# M55M1 register map
File version: 1.0
Registers are 32-bit, read-write, reset 0x0 unless marked. A register's access mark holds for its fields unless they carry their own. Offsets are from the block's base; [hi:lo] are bit positions; {n}, {i} and the like mark numbered series.

## DMIC — DMIC Register Map
Base 0x40445000
0x00 DMIC_CTL reset 0xF0000000 — DMIC Control Register
0x04 DMIC_DIV reset 0x800 — DMIC Clock Divider Register
0x08 DMIC_STATUS ro reset 0x2 (reset mask 0xFFFF)
0x0C DMIC_LPPDMACTL — DMIC LPPDMA Control Register
0x10 DMIC_FIFO ro — DMIC FIFO Data Output Register
0x14 DMIC_GAINCTL0 reset 0xC000C000 — DMIC Channel 0 and 1 Volume Control Register
0x18 DMIC_GAINCTL1 reset 0xC000C000 — DMIC Channel 2 and 3 Volume Control Register

## VAD — DMIC Register Map
Base 0x40445300
0x00 VAD_SINCCTL reset 0x30000 — VAD SINC Filter Control Register
{0x4+4i} VAD_BIQCTL{i} (i=0..2) — VAD Biquad Filter Control Register {i}
0x10 VAD_CTL0 reset 0x700CC — VAD Control Register 0
0x14 VAD_CTL1 reset 0x7FFF — VAD Control Register 1
0x18 VAD_CTL2 — VAD Control Register 2
0x1C VAD_CTL3 reset 0x7FFF — VAD Control Register 3
0x20 VAD_STATUS0 ro — VAD Status Read-back Register 0
0x24 VAD_STATUS1 ro — VAD Status Read-back Register 1

## KDF — KDF Register Map
Base 0x40221000
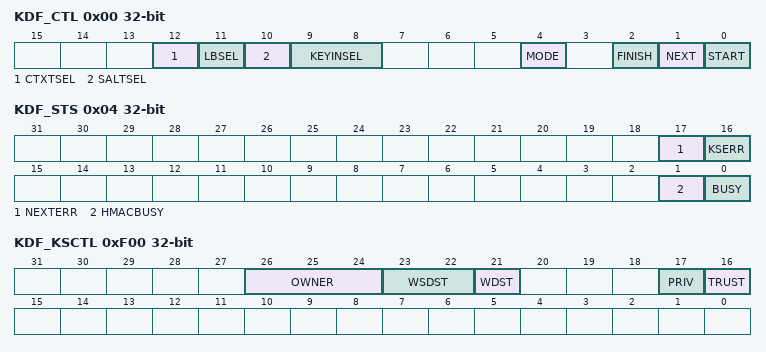
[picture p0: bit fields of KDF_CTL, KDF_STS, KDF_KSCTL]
0x00 KDF_CTL — KDF Control Register
  [12] CTXTSEL — KDF Context Selection
    0=CONTEXT from KDF_CONTEXT register; 1=CONTEXT from random value
  [11] LBSEL — KDF Label Selection
    0=LABEL from KDF_LABEL register; 1=LABEL from random value
  [10] SALTSEL — KDF Salt Selection
    0=SALT from KDF_SALT register; 1=SALT from random value
  [9:8] KEYINSEL — KDF Input Key Source Selection. Note: If KEYINSEL is 01, the NVM key is from KS OTP key 15.
    0=KEYIN from KDF_KEYIN register; 1=KEYIN from NVM (Flash)
  [4] MODE — KDF Mode Selection
    0=HKDF (RFC 5869); 1=KBKDF (NIST SP 800-108)
  [2] FINISH — KDF Next Finish
    0=No effect; 1=Finish generating the next partial key
  [1] NEXT — KDF Next Start
    0=No effect; 1=Start KDF to generate the next partial key only when BUSY is 0. BUSY flag will be set
  [0] START — KDF Start
    0=No operation; 1=Start the operation
0x04 KDF_STS ro — KDF Status Register
  [17] NEXTERR — KDF Next Generation Error Flag
    0=No error; 1=NEXT(KS_CTL[1]) times is greater than KLEN/256
  [16] KSERR — KDF Access Key Store Error Flag
    0=No error; 1=Access Key Store failed
  [1] HMACBUSY — HMAC Busy Flag
    0=HMAC engine is idle or finished; 1=HMAC engine is busy
  [0] BUSY — KDF Busy Flag
    0=KDF is idle or finished; 1=KDF is busy
0x08 KDF_KLEN — KDF Output Key Length Register
  [15:0] KLEN — Output Key Length. The maxinum is 0xFF00 (65280-bit). If KLEN is 0 or greater than the maximum, KDF will not execute.
{0x40+4i} KDF_KEYIN{i} wo (i=0..7) — KDF Input Key Word {i} Register
  [31:0] KEYIN — Input Key. For RFC 5869, input keying material is to be filled in KEYIN. For NIST SP 800-108, KI is to be filled in KEYIN.
{0x80+4i} KDF_KEYOUT{i} ro (i=0..7) — KDF Output Key Word {i} Register
  [31:0] KEYOUT — Output Key. These register bits will be cleared if CPU completes reading key.
{0x100+4i} KDF_SALT{i} wo (i=0..7)
  [31:0] SALT — Salt. These register bits are for RFC 5869.
{0x200+4i} KDF_LABEL{i} wo (i=0..2)
  [31:0] LABEL — Label. For RFC 5869, partial info is to be filled in LABEL according to Figure 6.592. For NIST SP 800-108, Label is to be filled in LABEL.
{0x280+4i} KDF_CTXT{i} wo (i=0..3) — KDF Context {i} Register
  [31:0] CTXT — Context. For RFC 5869, partial info is to be filled in CTXT according to Figure 6.592. For NIST SP 800-108, Context is to be filled in CTXT.
0xF00 KDF_KSCTL wo — KDF Output Key Control Register
  [26:24] OWNER — Write Key Owner Selection Bits
    0=Only for AES use; 1=Only for HMAC engine use; 4=Only for ECC engine use; 5=Only for CPU engine use
  [23:22] WSDST — Write Key Store Destination
    0=Key is written to the SRAM of Key Store; 1=Key is written to the Flash of Key Store
  [21] WDST — Write Key Destination
    0=Key is written to KDF_KEYOUT register; 1=Key is written to Key Store
  [17] PRIV — Write Key Priviledge Selection Bit
    0=Set written key as the non-priviledged key; 1=Set written key as the priviledged key
  [16] TRUST — Write Key Trust Selection Bit
    0=Set written key as the non-secure key; 1=Set written key as the secure key
0xF04 KDF_KSSTS ro — KDF Output Key Status Register
  [4:0] NUM — Key Number. The key number is generated by Key Store.
0xF08 KDF_KSSIZE — KDF Output Key Size Register
  [3:0] SIZE — Key Size Selection Bits
    0=128 bits; 1=163 bits; 2=192 bits; 3=224 bits; 4=233 bits; 5=255 bits; 6=256 bits; 7=283 bits; 8=384 bits; 9=409 bits; 10=512 bits; 11=521 bits; 12=571 bits
